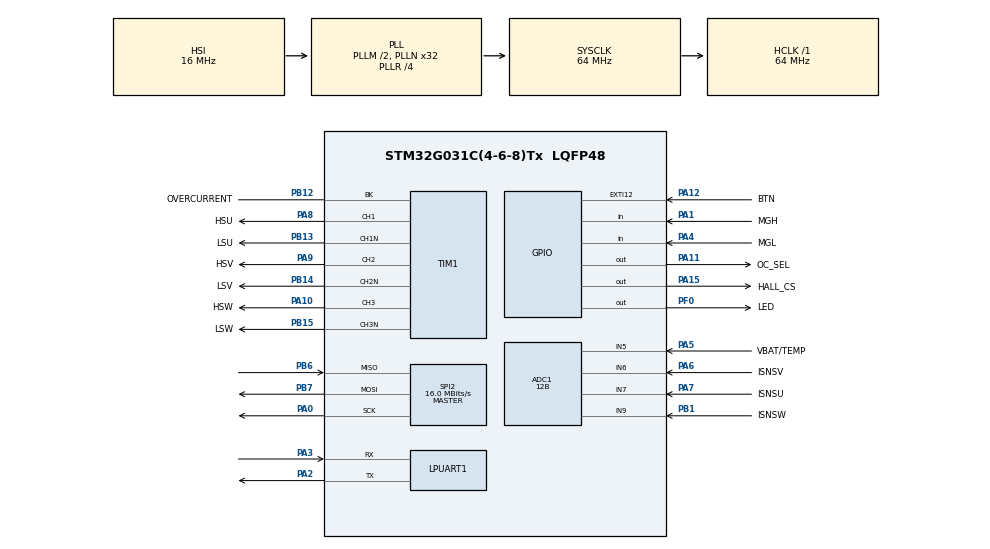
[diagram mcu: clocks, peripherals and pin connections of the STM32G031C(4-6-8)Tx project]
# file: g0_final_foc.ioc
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ADC1.ClockPrescaler=ADC_CLOCK_ASYNC_DIV1
ADC1.ContinuousConvMode=DISABLE
ADC1.DMAContinuousRequests=DISABLE
ADC1.DataAlign=ADC_DATAALIGN_LEFT
ADC1.DiscontinuousConvMode=DISABLE
ADC1.EOCSelection=ADC_EOC_SEQ_CONV
ADC1.EnableAnalogWatchDog1=false
ADC1.ExternalTrigConv=ADC_EXTERNALTRIG_T1_CC4
ADC1.ExternalTrigConvEdge=ADC_EXTERNALTRIGCONVEDGE_RISING
ADC1.LowPowerAutoPowerOff=DISABLE
ADC1.LowPowerAutoWait=DISABLE
ADC1.NbrOfConversion=1
ADC1.NbrOfConversionFlag=0
ADC1.Overrun=ADC_OVR_DATA_OVERWRITTEN
ADC1.OversamplingMode=DISABLE
ADC1.Resolution=ADC_RESOLUTION_12B
ADC1.SamplingTimeCommon1=ADC_SAMPLETIME_7CYCLES_5
ADC1.ScanConvMode=ADC_SCAN_SEQ_FIXED
ADC1.SelectedChannel=ADC_CHANNEL_5|ADC_CHANNEL_6|ADC_CHANNEL_7|ADC_CHANNEL_9
ADC1.Sequencer=NOT_FULLY_CONFIGURABLE
ADC1.TriggerFrequencyMode=ADC_TRIGGER_FREQ_HIGH
ADC1.master=1
Dma.ADC1.0.Direction=DMA_PERIPH_TO_MEMORY
Dma.ADC1.0.EventEnable=DISABLE
Dma.ADC1.0.Instance=DMA1_Channel1
Dma.ADC1.0.MemDataAlignment=DMA_MDATAALIGN_HALFWORD
Dma.ADC1.0.MemInc=DMA_MINC_ENABLE
Dma.ADC1.0.Mode=DMA_CIRCULAR
Dma.ADC1.0.PeriphDataAlignment=DMA_PDATAALIGN_HALFWORD
Dma.ADC1.0.PeriphInc=DMA_PINC_DISABLE
Dma.ADC1.0.Polarity=HAL_DMAMUX_REQ_GEN_RISING
Dma.ADC1.0.Priority=DMA_PRIORITY_HIGH
Dma.ADC1.0.RequestNumber=1
Dma.ADC1.0.SignalID=NONE
Dma.ADC1.0.SyncEnable=DISABLE
Dma.ADC1.0.SyncPolarity=HAL_DMAMUX_SYNC_NO_EVENT
Dma.ADC1.0.SyncRequestNumber=1
Dma.ADC1.0.SyncSignalID=NONE
Dma.LPUART1_RX.1.Direction=DMA_PERIPH_TO_MEMORY
Dma.LPUART1_RX.1.EventEnable=DISABLE
Dma.LPUART1_RX.1.Instance=DMA1_Channel2
Dma.LPUART1_RX.1.MemDataAlignment=DMA_MDATAALIGN_BYTE
Dma.LPUART1_RX.1.MemInc=DMA_MINC_ENABLE
Dma.LPUART1_RX.1.Mode=DMA_NORMAL
Dma.LPUART1_RX.1.PeriphDataAlignment=DMA_PDATAALIGN_BYTE
Dma.LPUART1_RX.1.PeriphInc=DMA_PINC_DISABLE
Dma.LPUART1_RX.1.Polarity=HAL_DMAMUX_REQ_GEN_RISING
Dma.LPUART1_RX.1.Priority=DMA_PRIORITY_LOW
Dma.LPUART1_RX.1.RequestNumber=1
Dma.LPUART1_RX.1.SignalID=NONE
Dma.LPUART1_RX.1.SyncEnable=DISABLE
Dma.LPUART1_RX.1.SyncPolarity=HAL_DMAMUX_SYNC_NO_EVENT
Dma.LPUART1_RX.1.SyncRequestNumber=1
Dma.LPUART1_RX.1.SyncSignalID=NONE
Dma.LPUART1_TX.2.Direction=DMA_MEMORY_TO_PERIPH
Dma.LPUART1_TX.2.EventEnable=DISABLE
Dma.LPUART1_TX.2.Instance=DMA1_Channel3
Dma.LPUART1_TX.2.MemDataAlignment=DMA_MDATAALIGN_BYTE
Dma.LPUART1_TX.2.MemInc=DMA_MINC_ENABLE
Dma.LPUART1_TX.2.Mode=DMA_NORMAL
Dma.LPUART1_TX.2.PeriphDataAlignment=DMA_PDATAALIGN_BYTE
Dma.LPUART1_TX.2.PeriphInc=DMA_PINC_DISABLE
Dma.LPUART1_TX.2.Polarity=HAL_DMAMUX_REQ_GEN_RISING
Dma.LPUART1_TX.2.Priority=DMA_PRIORITY_LOW
Dma.LPUART1_TX.2.RequestNumber=1
Dma.LPUART1_TX.2.SignalID=NONE
Dma.LPUART1_TX.2.SyncEnable=DISABLE
Dma.LPUART1_TX.2.SyncPolarity=HAL_DMAMUX_SYNC_NO_EVENT
Dma.LPUART1_TX.2.SyncRequestNumber=1
Dma.LPUART1_TX.2.SyncSignalID=NONE
Dma.Request0=ADC1
Dma.Request1=LPUART1_RX
Dma.Request2=LPUART1_TX
Dma.Request3=SPI2_RX
Dma.SPI2_RX.3.Direction=DMA_PERIPH_TO_MEMORY
Dma.SPI2_RX.3.EventEnable=DISABLE
Dma.SPI2_RX.3.Instance=DMA1_Channel4
Dma.SPI2_RX.3.MemDataAlignment=DMA_MDATAALIGN_BYTE
Dma.SPI2_RX.3.MemInc=DMA_MINC_ENABLE
Dma.SPI2_RX.3.Mode=DMA_NORMAL
Dma.SPI2_RX.3.PeriphDataAlignment=DMA_PDATAALIGN_BYTE
Dma.SPI2_RX.3.PeriphInc=DMA_PINC_DISABLE
Dma.SPI2_RX.3.Polarity=HAL_DMAMUX_REQ_GEN_RISING
Dma.SPI2_RX.3.Priority=DMA_PRIORITY_LOW
Dma.SPI2_RX.3.RequestNumber=1
Dma.SPI2_RX.3.SignalID=NONE
Dma.SPI2_RX.3.SyncEnable=DISABLE
Dma.SPI2_RX.3.SyncPolarity=HAL_DMAMUX_SYNC_NO_EVENT
Dma.SPI2_RX.3.SyncRequestNumber=1
Dma.SPI2_RX.3.SyncSignalID=NONE
Mcu.Family=STM32G0
Mcu.Name=STM32G031C(4-6-8)Tx
Mcu.Package=LQFP48
NVIC.DMA1_Channel1_IRQn=true\:1\:0\:true\:true\:false\:2\:true\:true\:true
NVIC.TIM1_BRK_UP_TRG_COM_IRQn=true\:0\:0\:false\:true\:false\:4\:true\:true\:true
NVIC.TIM1_CC_IRQn=true\:0\:0\:false\:false\:true\:true\:true\:true
PA0.Mode=Full_Duplex_Master
PA0.Signal=SPI2_SCK
PA1.GPIO_Label=MGH
PA1.Signal=GPIO_Input
PA10.GPIO_Label=HSW
PA10.GPIO_PuPd=GPIO_PULLDOWN
PA10.GPIO_Speed=GPIO_SPEED_FREQ_HIGH
PA10.Signal=S_TIM1_CH3
PA11\ [PA9].GPIO_Label=OC_SEL
PA11\ [PA9].GPIO_PuPd=GPIO_PULLDOWN
PA11\ [PA9].PinState=GPIO_PIN_SET
PA11\ [PA9].Signal=GPIO_Output
PA12\ [PA10].GPIO_Label=BTN
PA12\ [PA10].Signal=GPXTI12
PA13.Mode=Serial_Wire
PA13.Signal=SYS_SWDIO
PA14-BOOT0.Mode=Serial_Wire
PA14-BOOT0.Signal=SYS_SWCLK
PA15.GPIO_Label=HALL_CS
PA15.Signal=GPIO_Output
PA2.Mode=Asynchronous
PA2.Signal=LPUART1_TX
PA3.Mode=Asynchronous
PA3.Signal=LPUART1_RX
PA4.GPIO_Label=MGL
PA4.Signal=GPIO_Input
PA5.GPIO_Label=VBAT/TEMP
PA5.Mode=IN5
PA5.Signal=ADC1_IN5
PA6.GPIO_Label=ISNSV
PA6.Mode=IN6
PA6.Signal=ADC1_IN6
PA7.GPIO_Label=ISNSU
PA7.Mode=IN7
PA7.Signal=ADC1_IN7
PA8.GPIO_Label=HSU
PA8.GPIO_PuPd=GPIO_PULLDOWN
PA8.GPIO_Speed=GPIO_SPEED_FREQ_HIGH
PA8.Signal=S_TIM1_CH1
PA9.GPIO_Label=HSV
PA9.GPIO_PuPd=GPIO_PULLDOWN
PA9.GPIO_Speed=GPIO_SPEED_FREQ_HIGH
PA9.Signal=S_TIM1_CH2
PB1.GPIO_Label=ISNSW
PB1.Mode=IN9
PB1.Signal=ADC1_IN9
PB12.GPIO_Label=OVERCURRENT
PB12.GPIO_PuPd=GPIO_PULLDOWN
PB12.Mode=Activate-Break-Input
PB12.Signal=TIM1_BK
PB13.GPIO_Label=LSU
PB13.GPIO_PuPd=GPIO_PULLDOWN
PB13.GPIO_Speed=GPIO_SPEED_FREQ_HIGH
PB13.Mode=PWM Generation1 CH1 CH1N
PB13.Signal=TIM1_CH1N
PB14.GPIO_Label=LSV
PB14.GPIO_PuPd=GPIO_PULLDOWN
PB14.GPIO_Speed=GPIO_SPEED_FREQ_HIGH
PB14.Mode=PWM Generation2 CH2 CH2N
PB14.Signal=TIM1_CH2N
PB15.GPIO_Label=LSW
PB15.GPIO_PuPd=GPIO_PULLDOWN
PB15.GPIO_Speed=GPIO_SPEED_FREQ_HIGH
PB15.Mode=PWM Generation3 CH3 CH3N
PB15.Signal=TIM1_CH3N
PB6.Mode=Full_Duplex_Master
PB6.Signal=SPI2_MISO
PB7.Mode=Full_Duplex_Master
PB7.Signal=SPI2_MOSI
PF0-OSC_IN\ (PF0).GPIO_Label=LED
PF0-OSC_IN\ (PF0).Signal=GPIO_Output
ProjectManager.HeapSize=0x200
ProjectManager.StackSize=0x400
ProjectManager.TargetToolchain=STM32CubeIDE
RCC.ADCCLockSelection=RCC_ADCCLKSOURCE_PLLADC
RCC.ADCFreq_Value=32000000
RCC.AHBFreq_Value=64000000
RCC.CortexFreq_Value=64000000
RCC.EXTERNAL_CLOCK_VALUE=12288000
RCC.HCLKFreq_Value=64000000
RCC.HSE_VALUE=8000000
RCC.HSI_VALUE=16000000
RCC.LSE_VALUE=32768
RCC.PLLM=RCC_PLLM_DIV2
RCC.PLLN=32
RCC.PLLP=RCC_PLLP_DIV8
RCC.PLLQ=RCC_PLLQ_DIV2
RCC.PLLR=RCC_PLLR_DIV4
RCC.PLLSourceVirtual=RCC_PLLSOURCE_HSI
RCC.PREFETCH_ENABLE=1
RCC.SYSCLKFreq_VALUE=64000000
RCC.SYSCLKSource=RCC_SYSCLKSOURCE_PLLCLK
RCC.TIM1CLockSelectionVirtual=RCC_TIM1CLKSOURCE_PLL
RCC.VCOOutputFreq_Value=256000000
SH.S_TIM1_CH1.0=TIM1_CH1,PWM Generation1 CH1 CH1N
SH.S_TIM1_CH2.0=TIM1_CH2,PWM Generation2 CH2 CH2N
SH.S_TIM1_CH3.0=TIM1_CH3,PWM Generation3 CH3 CH3N
SPI2.BaudRatePrescaler=SPI_BAUDRATEPRESCALER_4
SPI2.CalculateBaudRate=16.0 MBits/s
SPI2.Direction=SPI_DIRECTION_2LINES
SPI2.Mode=SPI_MODE_MASTER
SPI2.VirtualType=VM_MASTER
TIM1.AutoReloadPreload=TIM_AUTORELOAD_PRELOAD_DISABLE
TIM1.AutomaticOutput=TIM_AUTOMATICOUTPUT_DISABLE
TIM1.Break2Filter=3
TIM1.Break2Polarity=TIM_BREAK2POLARITY_HIGH
TIM1.Break2State=TIM_BREAK2_DISABLE
TIM1.BreakAFMode=TIM_BREAK_AFMODE_INPUT
TIM1.BreakFilter=3
TIM1.BreakPolarity=TIM_BREAKPOLARITY_HIGH
TIM1.BreakState=TIM_BREAK_ENABLE
TIM1.Channel=TIM_CHANNEL_4
TIM1.Channel-PWM\ Generation1\ CH1\ CH1N=TIM_CHANNEL_1
TIM1.Channel-PWM\ Generation2\ CH2\ CH2N=TIM_CHANNEL_2
TIM1.Channel-PWM\ Generation3\ CH3\ CH3N=TIM_CHANNEL_3
TIM1.Channel-PWM\ Generation4\ No\ Output=TIM_CHANNEL_4
TIM1.ClearInputSource=TIM_CLEARINPUTSOURCE_NONE
TIM1.ClockDivision=TIM_CLOCKDIVISION_DIV1
TIM1.CounterMode=TIM_COUNTERMODE_CENTERALIGNED1
TIM1.DeadTime=((DEAD_TIME_COUNTS) / 2)
TIM1.LockLevel=TIM_LOCKLEVEL_OFF
TIM1.OC1Preload_PWM=ENABLE
TIM1.OC2Preload_PWM=ENABLE
TIM1.OC3Preload_PWM=ENABLE
TIM1.OC4Preload_PWM=ENABLE
TIM1.OCFastMode_PWM=TIM_OCFAST_DISABLE
TIM1.OCIdleState_1=TIM_OCIDLESTATE_RESET
TIM1.OCIdleState_2=TIM_OCIDLESTATE_RESET
TIM1.OCIdleState_3=TIM_OCIDLESTATE_RESET
TIM1.OCIdleState_4=TIM_OCIDLESTATE_RESET
TIM1.OCMode_PWM-PWM\ Generation1\ CH1\ CH1N=TIM_OCMODE_PWM1
TIM1.OCMode_PWM-PWM\ Generation2\ CH2\ CH2N=TIM_OCMODE_PWM1
TIM1.OCMode_PWM-PWM\ Generation3\ CH3\ CH3N=TIM_OCMODE_PWM1
TIM1.OCMode_PWM-PWM\ Generation4\ No\ Output=TIM_OCMODE_PWM2
TIM1.OCNIdleState_1=TIM_OCNIDLESTATE_RESET
TIM1.OCNIdleState_2=TIM_OCNIDLESTATE_RESET
TIM1.OCNIdleState_3=TIM_OCNIDLESTATE_RESET
TIM1.OCNPolarity_1=TIM_OCNPOLARITY_HIGH
TIM1.OCNPolarity_2=TIM_OCNPOLARITY_HIGH
TIM1.OCNPolarity_3=TIM_OCNPOLARITY_HIGH
TIM1.OCPolarity_1=TIM_OCPOLARITY_HIGH
TIM1.OCPolarity_2=TIM_OCPOLARITY_HIGH
TIM1.OCPolarity_3=TIM_OCPOLARITY_HIGH
TIM1.OCPolarity_4=TIM_OCPOLARITY_HIGH
TIM1.OffStateIDLEMode=TIM_OSSI_ENABLE
TIM1.OffStateRunMode=TIM_OSSR_ENABLE
TIM1.Period=((PWM_PERIOD_TICKS)-1)
TIM1.Prescaler=((TIM_CLOCK_DIVIDER) - 1)
TIM1.Pulse-PWM\ Generation1\ CH1\ CH1N=((PWM_PERIOD_TICKS) / 4)
TIM1.Pulse-PWM\ Generation2\ CH2\ CH2N=((PWM_PERIOD_TICKS) / 4)
TIM1.Pulse-PWM\ Generation3\ CH3\ CH3N=((PWM_PERIOD_TICKS) / 4)
TIM1.Pulse-PWM\ Generation4\ No\ Output=(((PWM_PERIOD_TICKS) / 2) - (HTMIN))
TIM1.RepetitionCounter=((FOC_UPDATE_EVENT_DIV)-1)
TIM1.SourceBRK2DigInput=TIM_BREAKINPUTSOURCE_DISABLE
TIM1.SourceBRKDigInput=TIM_BREAKINPUTSOURCE_ENABLE
TIM1.SourceBRKDigInputPolarity=TIM_BREAKINPUTSOURCE_POLARITY_HIGH
TIM1.TIM_MasterOutputTrigger=TIM_TRGO_OC4REF
TIM1.TIM_MasterOutputTrigger2=TIM_TRGO2_RESET
TIM1.TIM_MasterSlaveMode=TIM_MASTERSLAVEMODE_DISABLE
VP_TIM1_VS_no_output4.Mode=PWM Generation4 No Output
board=custom

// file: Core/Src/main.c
/* USER CODE BEGIN Header */
/**
  ******************************************************************************
  * @file           : main.c
  * @brief          : Main program body
  ******************************************************************************
  * @attention
  *
  * Copyright (c) 2025 STMicroelectronics.
  * All rights reserved.
  *
  * This software is licensed under terms that can be found in the LICENSE file
  * in the root directory of this software component.
  * If no LICENSE file comes with this software, it is provided AS-IS.
  *
  ******************************************************************************
  */
/* USER CODE END Header */
#include "main.h"
#include "adc.h"
#include "dma.h"
#include "usart.h"
#include "spi.h"
#include "tim.h"
#include "gpio.h"

/* USER CODE BEGIN Includes */
#include "foc.h"
#include "mps330.h"
/* USER CODE END Includes */

void SystemClock_Config(void);
static void MX_NVIC_Init(void);

int main(void)
{

  /* MCU Configuration--------------------------------------------------------*/

  /* Reset of all peripherals, Initializes the Flash interface and the Systick. */
  HAL_Init();

  /* Configure the system clock */
  SystemClock_Config();

  /* Initialize all configured peripherals */
  MX_GPIO_Init();
  MX_DMA_Init();
  MX_ADC1_Init();
  MX_TIM1_Init();
  MX_LPUART1_UART_Init();
  MX_SPI2_Init();

  /* Initialize interrupts */
  MX_NVIC_Init();
  /* USER CODE BEGIN 2 */

  HAL_TIM_PWM_Start(&htim1,TIM_CHANNEL_1);

  /* USER CODE END 2 */

  /* Infinite loop */
  while (1)
  {
	  HAL_GPIO_TogglePin(GPIOF,GPIO_PIN_0);
	  HAL_Delay(100);

  }
}

void SystemClock_Config(void)
{
  RCC_OscInitTypeDef RCC_OscInitStruct = {0};
  RCC_ClkInitTypeDef RCC_ClkInitStruct = {0};

  /** Configure the main internal regulator output voltage
  */
  HAL_PWREx_ControlVoltageScaling(PWR_REGULATOR_VOLTAGE_SCALE1);

  /** Initializes the RCC Oscillators according to the specified parameters
  * in the RCC_OscInitTypeDef structure.
  */
  RCC_OscInitStruct.OscillatorType = RCC_OSCILLATORTYPE_HSI;
  RCC_OscInitStruct.HSIState = RCC_HSI_ON;
  RCC_OscInitStruct.HSIDiv = RCC_HSI_DIV1;
  RCC_OscInitStruct.HSICalibrationValue = RCC_HSICALIBRATION_DEFAULT;
  RCC_OscInitStruct.PLL.PLLState = RCC_PLL_ON;
  RCC_OscInitStruct.PLL.PLLSource = RCC_PLLSOURCE_HSI;
  RCC_OscInitStruct.PLL.PLLM = RCC_PLLM_DIV2;
  RCC_OscInitStruct.PLL.PLLN = 32;
  RCC_OscInitStruct.PLL.PLLP = RCC_PLLP_DIV8;
  RCC_OscInitStruct.PLL.PLLQ = RCC_PLLQ_DIV2;
  RCC_OscInitStruct.PLL.PLLR = RCC_PLLR_DIV4;
  if (HAL_RCC_OscConfig(&RCC_OscInitStruct) != HAL_OK)
  {
    Error_Handler();
  }

  /** Initializes the CPU, AHB and APB buses clocks
  */
  RCC_ClkInitStruct.ClockType = RCC_CLOCKTYPE_HCLK|RCC_CLOCKTYPE_SYSCLK
                              |RCC_CLOCKTYPE_PCLK1;
  RCC_ClkInitStruct.SYSCLKSource = RCC_SYSCLKSOURCE_PLLCLK;
  RCC_ClkInitStruct.AHBCLKDivider = RCC_SYSCLK_DIV1;
  RCC_ClkInitStruct.APB1CLKDivider = RCC_HCLK_DIV1;

  if (HAL_RCC_ClockConfig(&RCC_ClkInitStruct, FLASH_LATENCY_2) != HAL_OK)
  {
    Error_Handler();
  }
}

/**
  * @brief NVIC Configuration.
  * @retval None
  */
static void MX_NVIC_Init(void)
{
  /* DMA1_Channel1_IRQn interrupt configuration */
  HAL_NVIC_SetPriority(DMA1_Channel1_IRQn, 1, 0);
  HAL_NVIC_EnableIRQ(DMA1_Channel1_IRQn);
  /* TIM1_BRK_UP_TRG_COM_IRQn interrupt configuration */
  HAL_NVIC_SetPriority(TIM1_BRK_UP_TRG_COM_IRQn, 0, 0);
  HAL_NVIC_EnableIRQ(TIM1_BRK_UP_TRG_COM_IRQn);
}

void Error_Handler(void)
{
  __disable_irq();
  while (1)
  {
  }
}
